AUTOSAR XML (schema 00046)
package /SWComponent
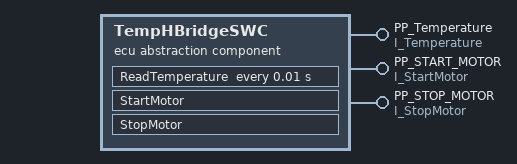
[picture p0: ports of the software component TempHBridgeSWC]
  ecu abstraction sw component type TempHBridgeSWC
    provide port PP_Temperature: provided-interface=I_Temperature
    provide port PP_START_MOTOR: provided-interface=I_StartMotor
    provide port PP_STOP_MOTOR: provided-interface=I_StopMotor
    behavior IB_Swc
      timing event TE_10ms: start-on-event=ReadTemperature, period=0.01
      operation invoked event OIE_StartMotor: start-on-event=StartMotor, operation=PP_StartMotor.StartMotor
      operation invoked event OIE_StopMotor: start-on-event=StopMotor, operation=PP_StopMotor.StopMotor
      runnable ReadTemperature: symbol=ReadTemperature_Function
        data-send-points:
          access VA_Temp: accessed-variable=PP_Temperature.Temperature
      runnable StartMotor: symbol=StartMotor_Function
      runnable StopMotor: symbol=StopMotor_Function
